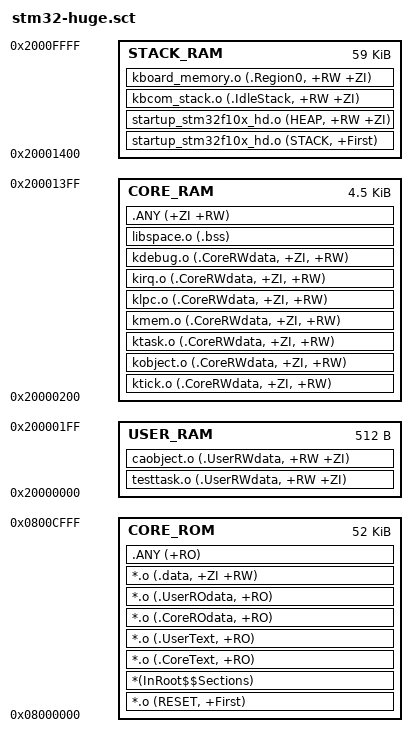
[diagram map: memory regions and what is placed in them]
; *************************************************************
; *** Scatter-Loading Description File generated by uVision ***
; *************************************************************

LR_IROM1 0x08000000 0x0000D000  {    ; load region size_region
  CORE_ROM 0x08000000 0x0000D000  {  ; load address = execution address
   *.o (RESET, +First)
   *(InRoot$$Sections)
   *.o (.CoreText, +RO)
   *.o (.UserText, +RO)
   *.o (.CoreROdata, +RO)
   *.o (.UserROdata, +RO)
   *.o (.data, +ZI +RW)
   .ANY (+RO)
  }

  USER_RAM 0x20000000 0x00000200  {  ; RW data
   testtask.o (.UserRWdata, +RW +ZI)
   caobject.o (.UserRWdata, +RW +ZI)
  }

  CORE_RAM 0x20000200 0x00001200  {  ; RW data
   ktick.o (.CoreRWdata, +ZI, +RW)
   kobject.o (.CoreRWdata, +ZI, +RW)
   ktask.o (.CoreRWdata, +ZI, +RW)
   kmem.o (.CoreRWdata, +ZI, +RW)
   klpc.o (.CoreRWdata, +ZI, +RW)
   kirq.o (.CoreRWdata, +ZI, +RW)
   kdebug.o (.CoreRWdata, +ZI, +RW)
   libspace.o (.bss)
   .ANY (+ZI +RW)
  }

  STACK_RAM 0x20001400 0x0000ec00  {  ; RW data
   startup_stm32f10x_hd.o (STACK, +First)
   startup_stm32f10x_hd.o (HEAP, +RW +ZI)
   kbcom_stack.o (.IdleStack, +RW +ZI)
   kboard_memory.o (.Region0, +RW +ZI)
;   kbstm32_stack.o (.CoreStack, +RW +ZI)
  }
}

